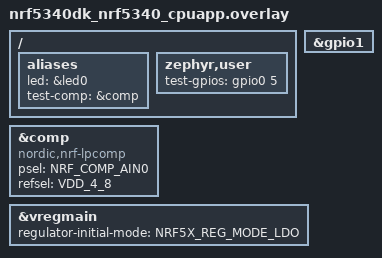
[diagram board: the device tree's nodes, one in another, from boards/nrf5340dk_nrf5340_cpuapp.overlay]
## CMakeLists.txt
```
#
# Copyright (c) 2024 Nordic Semiconductor ASA
#
# SPDX-License-Identifier: LicenseRef-Nordic-5-Clause
#

cmake_minimum_required(VERSION 3.20.0)
find_package(Zephyr REQUIRED HINTS $ENV{ZEPHYR_BASE})
zephyr_include_directories(include)

project(lpcomp)

target_sources(app PRIVATE ./../common/main.c)
target_sources(app PRIVATE src/driver_test.c)
```

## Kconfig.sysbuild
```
#
# Copyright (c) 2024 Nordic Semiconductor ASA
#
# SPDX-License-Identifier: LicenseRef-Nordic-5-Clause
#

config REMOTE_BOARD
	string
	default "$(BOARD)/nrf54h20/cpurad" if SOC_NRF54H20_CPUAPP

source "share/sysbuild/Kconfig"
```

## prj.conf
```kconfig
CONFIG_COMPARATOR=y
CONFIG_GPIO=y

# Enable runtime power management for peripheral
CONFIG_PM_DEVICE=y
CONFIG_PM_DEVICE_RUNTIME=y

CONFIG_PM=y
CONFIG_POWEROFF=y
CONFIG_CONSOLE=n
CONFIG_UART_CONSOLE=n
CONFIG_SERIAL=n
CONFIG_POWEROFF=y
CONFIG_BOOT_BANNER=n
CONFIG_NCS_BOOT_BANNER=n
CONFIG_ASSERT=y
```

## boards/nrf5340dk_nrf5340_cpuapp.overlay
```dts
/*
 * Copyright (c) 2025 Nordic Semiconductor ASA
 *
 * SPDX-License-Identifier: LicenseRef-Nordic-5-Clause
 */

#include <zephyr/dt-bindings/comparator/nrf-comp.h>

/ {
	aliases {
		led = &led0;
		test-comp = &comp;
	};

	zephyr,user {
		test-gpios = <&gpio0 5 GPIO_ACTIVE_HIGH>;
	};
};

&gpio1 {
	status = "okay";
};

&comp {
	compatible = "nordic,nrf-lpcomp";
	psel = <NRF_COMP_AIN0>; /* P0.04 */
	refsel = "VDD_4_8";
	status = "okay";
};

&vregmain {
	regulator-initial-mode = <NRF5X_REG_MODE_LDO>;
};
```

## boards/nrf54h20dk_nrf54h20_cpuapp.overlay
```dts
/*
 * Copyright (c) 2024 Nordic Semiconductor ASA
 *
 * SPDX-License-Identifier: LicenseRef-Nordic-5-Clause
 */

#include <zephyr/dt-bindings/comparator/nrf-comp.h>

/ {
	aliases {
		led = &led0;
		/delete-property/ led1;
		test-comp = &comp;
	};

	zephyr,user {
		test-gpios = <&gpio1 3 GPIO_ACTIVE_HIGH>;
	};
};

/delete-node/ &led1;

&gpio1 {
	status = "okay";
};

&comp {
	compatible = "nordic,nrf-lpcomp";
	psel = <NRF_COMP_AIN2>; /* P1.02 */
	refsel = "VDD_4_8";
	status = "okay";
	zephyr,pm-device-runtime-auto;
};
```

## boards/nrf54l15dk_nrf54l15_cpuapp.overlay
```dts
/*
 * Copyright (c) 2024 Nordic Semiconductor ASA
 *
 * SPDX-License-Identifier: LicenseRef-Nordic-5-Clause
 */

#include <zephyr/dt-bindings/comparator/nrf-comp.h>

/ {
	aliases {
		led = &button3;
		test-comp = &comp;
	};

	zephyr,user {
		test-gpios = <&gpio1 10 GPIO_ACTIVE_HIGH>;
	};
};

&gpio1 {
	status = "okay";
};

&comp {
	compatible = "nordic,nrf-lpcomp";
	psel = <NRF_COMP_AIN4>; /* P1.11 */
	refsel = "VDD_4_8";
	status = "okay";
};
```

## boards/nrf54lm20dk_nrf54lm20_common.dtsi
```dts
/*
 * Copyright (c) 2026 Nordic Semiconductor ASA
 *
 * SPDX-License-Identifier: LicenseRef-Nordic-5-Clause
 */

#include <zephyr/dt-bindings/comparator/nrf-comp.h>

/ {
	aliases {
		led = &led0;
		/delete-property/ led1;
		test-comp = &comp;
	};

	zephyr,user {
		test-gpios = <&gpio1 30 GPIO_ACTIVE_HIGH>;
	};
};

/delete-node/ &led1;

&gpio1 {
	status = "okay";
};

&comp {
	compatible = "nordic,nrf-lpcomp";
	psel = <NRF_COMP_AIN1>; /* P1.31 */
	refsel = "VDD_4_8";
	status = "okay";
};
```

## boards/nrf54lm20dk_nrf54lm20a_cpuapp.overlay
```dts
/*
 * Copyright (c) 2024 Nordic Semiconductor ASA
 *
 * SPDX-License-Identifier: LicenseRef-Nordic-5-Clause
 */

#include <zephyr/dt-bindings/comparator/nrf-comp.h>

/ {
	aliases {
		led = &led0;
		/delete-property/ led1;
		test-comp = &comp;
	};

	zephyr,user {
		test-gpios = <&gpio1 30 GPIO_ACTIVE_HIGH>;
	};
};

/delete-node/ &led1;

&gpio1 {
	status = "okay";
};

&comp {
	compatible = "nordic,nrf-lpcomp";
	psel = <NRF_COMP_AIN1>; /* P1.31 */
	refsel = "VDD_4_8";
	status = "okay";
};
```

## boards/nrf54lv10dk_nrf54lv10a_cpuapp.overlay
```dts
#include <zephyr/dt-bindings/comparator/nrf-comp.h>

/ {
	aliases {
		led = &led0;
		/delete-property/ led1;
		test-comp = &comp;
	};

	zephyr,user {
		test-gpios = <&gpio1 10 GPIO_ACTIVE_HIGH>;
	};
};

/delete-node/ &led1;

&gpio1 {
	status = "okay";
};

&comp {
	compatible = "nordic,nrf-lpcomp";
	psel = <NRF_COMP_AIN6>; /* P1.11 */
	refsel = "VDD_4_8";
	status = "okay";
};
```

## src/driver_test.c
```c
/*
 * Copyright (c) 2024 Nordic Semiconductor ASA
 *
 * SPDX-License-Identifier: LicenseRef-Nordic-5-Clause
 */

#include <zephyr/drivers/comparator.h>
#include <zephyr/drivers/gpio.h>
#include <zephyr/kernel.h>
#include <zephyr/pm/device_runtime.h>

static const struct device *test_dev = DEVICE_DT_GET(DT_ALIAS(test_comp));
static const struct gpio_dt_spec test_pin = GPIO_DT_SPEC_GET(DT_PATH(zephyr_user), test_gpios);

static volatile int counter;
static volatile bool suspend_req;

static void test_callback(const struct device *dev, void *user_data)
{
	int rc;

	rc = pm_device_runtime_put_async(dev, K_NO_WAIT);
	__ASSERT_NO_MSG(rc == 0);
	counter++;
}

bool self_suspend_req(void)
{
	suspend_req = true;
	return true;
}

void thread_definition(void)
{
	int rc;

	gpio_pin_configure_dt(&test_pin, GPIO_OUTPUT_INACTIVE);

	rc = comparator_set_trigger_callback(test_dev, test_callback, NULL);
	__ASSERT_NO_MSG(rc == 0);

	rc = comparator_set_trigger(test_dev, COMPARATOR_TRIGGER_BOTH_EDGES);
	__ASSERT_NO_MSG(rc == 0);
	k_msleep(10);

	while (1) {
		if (suspend_req) {
			suspend_req = false;
			k_thread_suspend(k_current_get());
		}

		rc = pm_device_runtime_get(test_dev);
		__ASSERT_NO_MSG(rc == 0);
		k_busy_wait(100);
		counter = 0;
		gpio_pin_set_dt(&test_pin, 1);
		k_msleep(10);
		__ASSERT_NO_MSG(counter == 1);

		rc = pm_device_runtime_get(test_dev);
		__ASSERT_NO_MSG(rc == 0);
		k_busy_wait(100);
		gpio_pin_set_dt(&test_pin, 0);
		k_msleep(10);
		__ASSERT_NO_MSG(counter == 2);
	}
};
```
